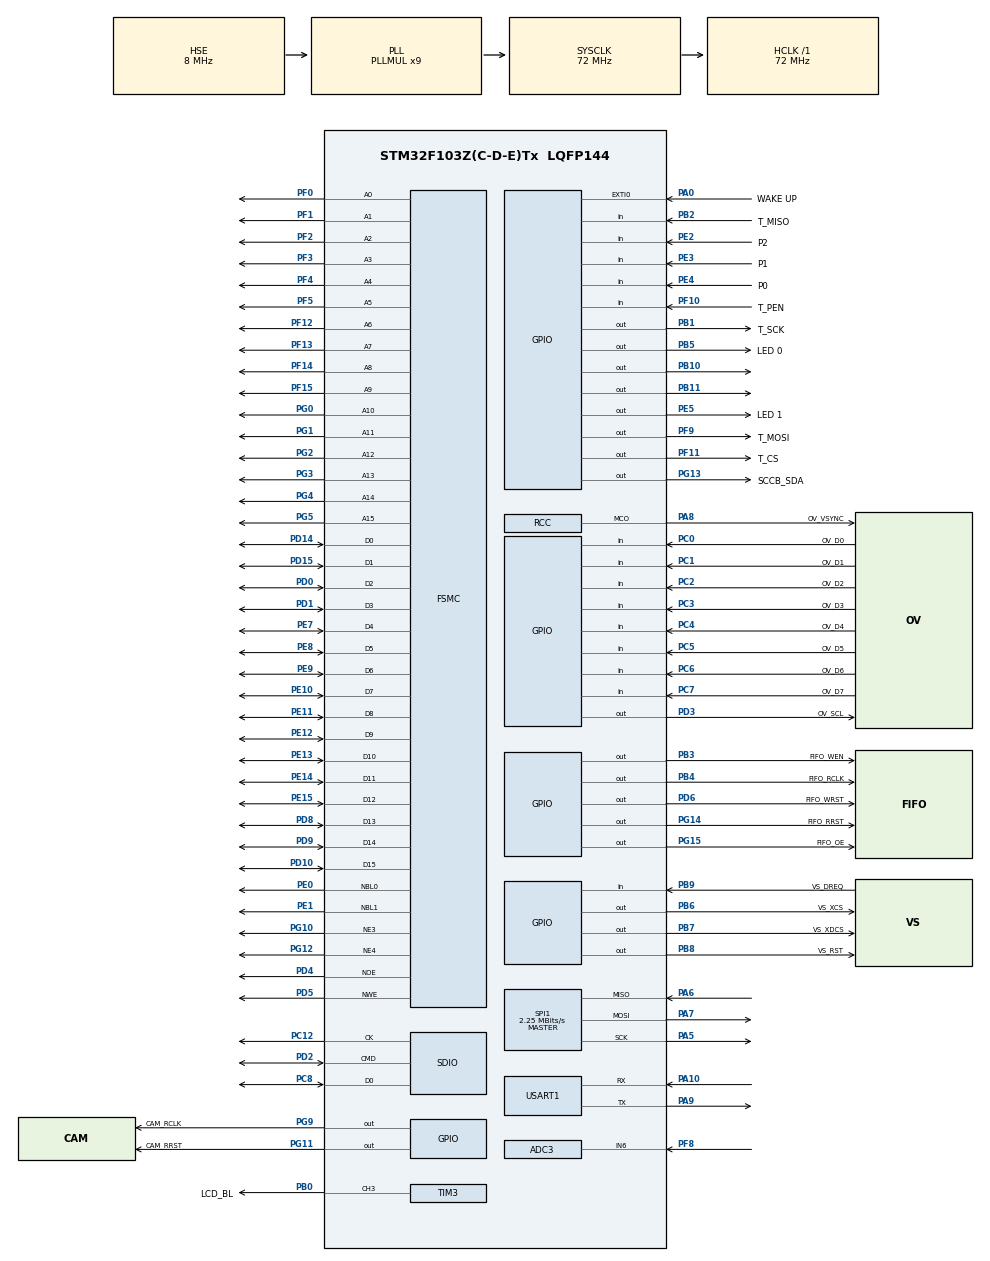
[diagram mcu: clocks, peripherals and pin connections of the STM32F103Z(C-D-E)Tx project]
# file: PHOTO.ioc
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ADC3.Channel-0\#ChannelRegularConversion=ADC_CHANNEL_6
ADC3.NbrOfConversionFlag=1
ADC3.Rank-0\#ChannelRegularConversion=1
ADC3.SamplingTime-0\#ChannelRegularConversion=ADC_SAMPLETIME_1CYCLE_5
Dma.Request0=SDIO
Dma.Request1=SPI1_TX
Dma.SDIO.0.Direction=DMA_PERIPH_TO_MEMORY
Dma.SDIO.0.Instance=DMA2_Channel4
Dma.SDIO.0.MemDataAlignment=DMA_MDATAALIGN_WORD
Dma.SDIO.0.MemInc=DMA_MINC_ENABLE
Dma.SDIO.0.Mode=DMA_NORMAL
Dma.SDIO.0.PeriphDataAlignment=DMA_PDATAALIGN_WORD
Dma.SDIO.0.PeriphInc=DMA_PINC_DISABLE
Dma.SDIO.0.Priority=DMA_PRIORITY_VERY_HIGH
Dma.SPI1_TX.1.Direction=DMA_MEMORY_TO_PERIPH
Dma.SPI1_TX.1.Instance=DMA1_Channel3
Dma.SPI1_TX.1.MemDataAlignment=DMA_MDATAALIGN_BYTE
Dma.SPI1_TX.1.MemInc=DMA_MINC_ENABLE
Dma.SPI1_TX.1.Mode=DMA_NORMAL
Dma.SPI1_TX.1.PeriphDataAlignment=DMA_PDATAALIGN_BYTE
Dma.SPI1_TX.1.PeriphInc=DMA_PINC_DISABLE
Dma.SPI1_TX.1.Priority=DMA_PRIORITY_HIGH
Mcu.Family=STM32F1
Mcu.Name=STM32F103Z(C-D-E)Tx
Mcu.Package=LQFP144
NVIC.ADC3_IRQn=true\:0\:0\:false\:false\:true\:true\:true\:true
NVIC.DMA1_Channel3_IRQn=true\:0\:0\:false\:false\:true\:false\:true\:true
NVIC.DMA2_Channel4_5_IRQn=true\:0\:0\:false\:false\:true\:false\:true\:true
NVIC.EXTI0_IRQn=true\:0\:0\:false\:false\:true\:true\:true\:true
NVIC.PriorityGroup=NVIC_PRIORITYGROUP_4
NVIC.SDIO_IRQn=true\:0\:0\:false\:false\:true\:true\:true\:true
NVIC.SPI1_IRQn=true\:0\:0\:false\:false\:true\:true\:true\:true
NVIC.TIM5_IRQn=true\:0\:0\:false\:false\:true\:true\:true\:true
NVIC.TIM6_IRQn=true\:0\:0\:false\:false\:true\:true\:true\:true
NVIC.USART1_IRQn=true\:0\:0\:false\:false\:true\:true\:true\:true
OSC_IN.Mode=HSE-External-Oscillator
OSC_IN.Signal=RCC_OSC_IN
OSC_OUT.Mode=HSE-External-Oscillator
OSC_OUT.Signal=RCC_OSC_OUT
PA0-WKUP.GPIO_Label=WAKE UP
PA0-WKUP.GPIO_ModeDefaultEXTI=GPIO_MODE_IT_RISING
PA0-WKUP.GPIO_PuPd=GPIO_PULLDOWN
PA0-WKUP.Signal=GPXTI0
PA10.Mode=Asynchronous
PA10.Signal=USART1_RX
PA5.Mode=Full_Duplex_Master
PA5.Signal=SPI1_SCK
PA6.Mode=Full_Duplex_Master
PA6.Signal=SPI1_MISO
PA7.Mode=Full_Duplex_Master
PA7.Signal=SPI1_MOSI
PA8.GPIO_Label=OV_VSYNC
PA8.GPIO_Speed=GPIO_SPEED_FREQ_HIGH
PA8.Mode=Clock-out
PA8.Signal=RCC_MCO
PA9.Mode=Asynchronous
PA9.Signal=USART1_TX
PB0.GPIO_Label=LCD_BL
PB0.Signal=S_TIM3_CH3
PB1.GPIO_Label=T_SCK
PB1.GPIO_Speed=GPIO_SPEED_FREQ_HIGH
PB1.Signal=GPIO_Output
PB10.GPIO_PuPd=GPIO_PULLUP
PB10.PinState=GPIO_PIN_SET
PB10.Signal=GPIO_Output
PB11.GPIO_ModeDefaultOutputPP=GPIO_MODE_OUTPUT_PP
PB11.GPIO_PuPd=GPIO_PULLUP
PB11.PinState=GPIO_PIN_SET
PB11.Signal=GPIO_Output
PB2.GPIO_Label=T_MISO
PB2.GPIO_PuPd=GPIO_PULLUP
PB2.Signal=GPIO_Input
PB3.GPIO_Label=FIFO_WEN
PB3.Signal=GPIO_Output
PB4.GPIO_Label=FIFO_RCLK
PB4.Signal=GPIO_Output
PB5.GPIO_Label=LED 0
PB5.PinState=GPIO_PIN_SET
PB5.Signal=GPIO_Output
PB6.GPIO_Label=VS_XCS
PB6.PinState=GPIO_PIN_SET
PB6.Signal=GPIO_Output
PB7.GPIO_Label=VS_XDCS
PB7.PinState=GPIO_PIN_SET
PB7.Signal=GPIO_Output
PB8.GPIO_Label=VS_RST
PB8.PinState=GPIO_PIN_SET
PB8.Signal=GPIO_Output
PB9.GPIO_Label=VS_DREQ
PB9.Signal=GPIO_Input
PC0.GPIO_Label=OV_D0
PC0.Signal=GPIO_Input
PC1.GPIO_Label=OV_D1
PC1.Signal=GPIO_Input
PC12.Mode=SD_1_bit
PC12.Signal=SDIO_CK
PC14-OSC32_IN.Mode=LSE-External-Oscillator
PC14-OSC32_IN.Signal=RCC_OSC32_IN
PC15-OSC32_OUT.Mode=LSE-External-Oscillator
PC15-OSC32_OUT.Signal=RCC_OSC32_OUT
PC2.GPIO_Label=OV_D2
PC2.Signal=GPIO_Input
PC3.GPIO_Label=OV_D3
PC3.Signal=GPIO_Input
PC4.GPIO_Label=OV_D4
PC4.Signal=GPIO_Input
PC5.GPIO_Label=OV_D5
PC5.Signal=GPIO_Input
PC6.GPIO_Label=OV_D6
PC6.Signal=GPIO_Input
PC7.GPIO_Label=OV_D7
PC7.Signal=GPIO_Input
PC8.Mode=SD_1_bit
PC8.Signal=SDIO_D0
PD0.Signal=FSMC_D2_DA2
PD1.Signal=FSMC_D3_DA3
PD10.Signal=FSMC_D15_DA15
PD14.Signal=FSMC_D0_DA0
PD15.Signal=FSMC_D1_DA1
PD2.Mode=SD_1_bit
PD2.Signal=SDIO_CMD
PD3.GPIO_Label=OV_SCL
PD3.Signal=GPIO_Output
PD4.Signal=FSMC_NOE
PD5.Signal=FSMC_NWE
PD6.GPIO_Label=FIFO_WRST
PD6.Signal=GPIO_Output
PD8.Signal=FSMC_D13_DA13
PD9.Signal=FSMC_D14_DA14
PE0.Signal=FSMC_NBL0
PE1.Signal=FSMC_NBL1
PE10.Signal=FSMC_D7_DA7
PE11.Signal=FSMC_D8_DA8
PE12.Signal=FSMC_D9_DA9
PE13.Signal=FSMC_D10_DA10
PE14.Signal=FSMC_D11_DA11
PE15.Signal=FSMC_D12_DA12
PE2.GPIO_Label=P2
PE2.GPIO_PuPd=GPIO_PULLUP
PE2.Signal=GPIO_Input
PE3.GPIO_Label=P1
PE3.GPIO_PuPd=GPIO_PULLUP
PE3.Signal=GPIO_Input
PE4.GPIO_Label=P0
PE4.GPIO_PuPd=GPIO_PULLUP
PE4.Signal=GPIO_Input
PE5.GPIO_Label=LED 1
PE5.PinState=GPIO_PIN_SET
PE5.Signal=GPIO_Output
PE7.Signal=FSMC_D4_DA4
PE8.Signal=FSMC_D5_DA5
PE9.Signal=FSMC_D6_DA6
PF0.Signal=FSMC_A0
PF1.Signal=FSMC_A1
PF10.GPIO_Label=T_PEN
PF10.GPIO_PuPd=GPIO_PULLUP
PF10.Signal=GPIO_Input
PF11.GPIO_Label=T_CS
PF11.GPIO_Speed=GPIO_SPEED_FREQ_HIGH
PF11.Signal=GPIO_Output
PF12.Signal=FSMC_A6
PF13.Signal=FSMC_A7
PF14.Signal=FSMC_A8
PF15.Signal=FSMC_A9
PF2.Signal=FSMC_A2
PF3.Signal=FSMC_A3
PF4.Signal=FSMC_A4
PF5.Signal=FSMC_A5
PF8.Mode=IN6
PF8.Signal=ADC3_IN6
PF9.GPIO_Label=T_MOSI
PF9.GPIO_Speed=GPIO_SPEED_FREQ_HIGH
PF9.Signal=GPIO_Output
PG0.Signal=FSMC_A10
PG1.Signal=FSMC_A11
PG10.Mode=NorPsramChipSelect3_2
PG10.Signal=FSMC_NE3
PG11.GPIO_Label=CAM_RRST
PG11.PinState=GPIO_PIN_SET
PG11.Signal=GPIO_Output
PG12.Mode=NorPsramChipSelect4_4
PG12.Signal=FSMC_NE4
PG13.GPIO_Label=SCCB_SDA
PG13.GPIO_ModeDefaultOutputPP=GPIO_MODE_OUTPUT_OD
PG13.GPIO_PuPd=GPIO_NOPULL
PG13.GPIO_Speed=GPIO_SPEED_FREQ_HIGH
PG13.PinState=GPIO_PIN_SET
PG13.Signal=GPIO_Output
PG14.GPIO_Label=FIFO_RRST
PG14.Signal=GPIO_Output
PG15.GPIO_Label=FIFO_OE
PG15.Signal=GPIO_Output
PG2.Signal=FSMC_A12
PG3.Signal=FSMC_A13
PG4.Signal=FSMC_A14
PG5.Signal=FSMC_A15
PG9.GPIO_Label=CAM_RCLK
PG9.GPIO_Speed=GPIO_SPEED_FREQ_HIGH
PG9.PinState=GPIO_PIN_SET
PG9.Signal=GPIO_Output
ProjectManager.HeapSize=0x200
ProjectManager.StackSize=0x400
ProjectManager.TargetToolchain=STM32CubeIDE
RCC.ADCPresc=RCC_ADCPCLK2_DIV8
RCC.AHBFreq_Value=72000000
RCC.APB1CLKDivider=RCC_HCLK_DIV2
RCC.APB1Freq_Value=36000000
RCC.APB1TimFreq_Value=72000000
RCC.APB2Freq_Value=72000000
RCC.APB2TimFreq_Value=72000000
RCC.HCLKFreq_Value=72000000
RCC.PLLMUL=RCC_PLL_MUL9
RCC.PLLSourceVirtual=RCC_PLLSOURCE_HSE
RCC.RCC_MCOSource=RCC_MCO1SOURCE_PLLCLK
RCC.SYSCLKFreq_VALUE=72000000
RCC.SYSCLKSource=RCC_SYSCLKSOURCE_PLLCLK
RCC.USBFreq_Value=72000000
SH.FSMC_A0.0=FSMC_A0,16b-a2
SH.FSMC_A1.0=FSMC_A1,16b-a2
SH.FSMC_A10.0=FSMC_A10,A10_4
SH.FSMC_A10.1=FSMC_A10,16b-a2
SH.FSMC_A11.0=FSMC_A11,16b-a2
SH.FSMC_A12.0=FSMC_A12,16b-a2
SH.FSMC_A13.0=FSMC_A13,16b-a2
SH.FSMC_A14.0=FSMC_A14,16b-a2
SH.FSMC_A15.0=FSMC_A15,16b-a2
SH.FSMC_A2.0=FSMC_A2,16b-a2
SH.FSMC_A3.0=FSMC_A3,16b-a2
SH.FSMC_A4.0=FSMC_A4,16b-a2
SH.FSMC_A5.0=FSMC_A5,16b-a2
SH.FSMC_A6.0=FSMC_A6,16b-a2
SH.FSMC_A7.0=FSMC_A7,16b-a2
SH.FSMC_A8.0=FSMC_A8,16b-a2
SH.FSMC_A9.0=FSMC_A9,16b-a2
SH.FSMC_D0_DA0.0=FSMC_D0,16b-d4
SH.FSMC_D0_DA0.1=FSMC_D0,16b-d2
SH.FSMC_D10_DA10.0=FSMC_D10,16b-d4
SH.FSMC_D10_DA10.1=FSMC_D10,16b-d2
SH.FSMC_D11_DA11.0=FSMC_D11,16b-d4
SH.FSMC_D11_DA11.1=FSMC_D11,16b-d2
SH.FSMC_D12_DA12.0=FSMC_D12,16b-d4
SH.FSMC_D12_DA12.1=FSMC_D12,16b-d2
SH.FSMC_D13_DA13.0=FSMC_D13,16b-d4
SH.FSMC_D13_DA13.1=FSMC_D13,16b-d2
SH.FSMC_D14_DA14.0=FSMC_D14,16b-d4
SH.FSMC_D14_DA14.1=FSMC_D14,16b-d2
SH.FSMC_D15_DA15.0=FSMC_D15,16b-d4
SH.FSMC_D15_DA15.1=FSMC_D15,16b-d2
SH.FSMC_D1_DA1.0=FSMC_D1,16b-d4
SH.FSMC_D1_DA1.1=FSMC_D1,16b-d2
SH.FSMC_D2_DA2.0=FSMC_D2,16b-d4
SH.FSMC_D2_DA2.1=FSMC_D2,16b-d2
SH.FSMC_D3_DA3.0=FSMC_D3,16b-d4
SH.FSMC_D3_DA3.1=FSMC_D3,16b-d2
SH.FSMC_D4_DA4.0=FSMC_D4,16b-d4
SH.FSMC_D4_DA4.1=FSMC_D4,16b-d2
SH.FSMC_D5_DA5.0=FSMC_D5,16b-d4
SH.FSMC_D5_DA5.1=FSMC_D5,16b-d2
SH.FSMC_D6_DA6.0=FSMC_D6,16b-d4
SH.FSMC_D6_DA6.1=FSMC_D6,16b-d2
SH.FSMC_D7_DA7.0=FSMC_D7,16b-d4
SH.FSMC_D7_DA7.1=FSMC_D7,16b-d2
SH.FSMC_D8_DA8.0=FSMC_D8,16b-d4
SH.FSMC_D8_DA8.1=FSMC_D8,16b-d2
SH.FSMC_D9_DA9.0=FSMC_D9,16b-d4
SH.FSMC_D9_DA9.1=FSMC_D9,16b-d2
SH.FSMC_NBL0.0=FSMC_NBL0,2ByteEnable2
SH.FSMC_NBL1.0=FSMC_NBL1,2ByteEnable2
SH.FSMC_NOE.0=FSMC_NOE,Lcd4
SH.FSMC_NOE.1=FSMC_NOE,Sram2
SH.FSMC_NWE.0=FSMC_NWE,Lcd4
SH.FSMC_NWE.1=FSMC_NWE,Sram2
SH.S_TIM3_CH3.0=TIM3_CH3,PWM Generation3 CH3
SPI1.BaudRatePrescaler=SPI_BAUDRATEPRESCALER_32
SPI1.CalculateBaudRate=2.25 MBits/s
SPI1.Direction=SPI_DIRECTION_2LINES
SPI1.Mode=SPI_MODE_MASTER
SPI1.VirtualType=VM_MASTER
TIM3.Channel-PWM\ Generation3\ CH3=TIM_CHANNEL_3
TIM3.Period=100
TIM3.Prescaler=71
TIM5.Period=1000
TIM5.Prescaler=71
TIM6.Period=5000
USART1.VirtualMode=VM_ASYNC
VP_FATFS_VS_SDIO.Mode=SDIO
VP_SYS_VS_ND.Mode=No_Debug
VP_TIM5_VS_ClockSourceINT.Mode=Internal
VP_TIM6_VS_ClockSourceINT.Mode=Enable_Timer
board=custom

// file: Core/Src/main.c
/* USER CODE BEGIN Header */
/**
  ******************************************************************************
  * @file           : main.c
  * @brief          : OV7670 + FIFO -> LCD Live Preview (Fixed version)
  ******************************************************************************
  */
/* USER CODE END Header */

#include "main.h"
#include "fatfs.h"
#include <stdio.h>
#include <string.h>

/* USER CODE BEGIN PD */

/* ── 누락된 컬러 및 주소 정의 추가 ── */
#define OV7670_ADDR_W  0x42
#define OV7670_ADDR_R  0x43

#define COLOR_WHITE  0xFFFF
#define COLOR_BLACK  0x0000
#define COLOR_RED    0xF800
#define COLOR_GREEN  0x07E0
#define COLOR_BLUE   0x001F
#define COLOR_YELLOW 0xFFE0

/* ── LCD 설정 ── */
#define LCD_W   240
#define LCD_H   320

/* ── FSMC LCD direct access (Bank 4, A10) ── */
#undef  BANK1_index
#undef  BANK1_A10_data
#define BANK1_index    (*(volatile uint16_t *)0x6C000000)
#define BANK1_A10_data (*(volatile uint16_t *)0x6C000800)
#define LCD_CMD   BANK1_index
#define LCD_DATA  BANK1_A10_data
#define LCD_xpos_cmd 0x2A
#define LCD_ypos_cmd 0x2B
#define LCD_wram_cmd 0x2C

/* ── OV7670 FIFO 제어 매크로 (main.h 이름으로 강제 매칭) ── */
#define CAM_RRST_H()  HAL_GPIO_WritePin(FIFO_RRST_GPIO_Port, FIFO_RRST_Pin, GPIO_PIN_SET)
#define CAM_RRST_L()  HAL_GPIO_WritePin(FIFO_RRST_GPIO_Port, FIFO_RRST_Pin, GPIO_PIN_RESET)
#define CAM_RCLK_H()  HAL_GPIO_WritePin(FIFO_RCLK_GPIO_Port, FIFO_RCLK_Pin, GPIO_PIN_SET)
#define CAM_RCLK_L()  HAL_GPIO_WritePin(FIFO_RCLK_GPIO_Port, FIFO_RCLK_Pin, GPIO_PIN_RESET)
#define CAM_WEN_H()   HAL_GPIO_WritePin(FIFO_WEN_GPIO_Port,  FIFO_WEN_Pin,  GPIO_PIN_SET)
#define CAM_WEN_L()   HAL_GPIO_WritePin(FIFO_WEN_GPIO_Port,  FIFO_WEN_Pin,  GPIO_PIN_RESET)
#define CAM_WRST_H()  HAL_GPIO_WritePin(FIFO_WRST_GPIO_Port, FIFO_WRST_Pin, GPIO_PIN_SET)
#define CAM_WRST_L()  HAL_GPIO_WritePin(FIFO_WRST_GPIO_Port, FIFO_WRST_Pin, GPIO_PIN_RESET)
#define CAM_OE_H()    HAL_GPIO_WritePin(FIFO_OE_GPIO_Port,   FIFO_OE_Pin,   GPIO_PIN_SET)
#define CAM_OE_L()    HAL_GPIO_WritePin(FIFO_OE_GPIO_Port,   FIFO_OE_Pin,   GPIO_PIN_RESET)

/* 카메라 데이터 버스 (PC0-PC7) */
#define CAM_READ_DATA() ((uint8_t)(GPIOC->IDR & 0xFF))

/* ── SCCB (Software I2C) 매크로 ── */
#define SCCB_SDA_H()    HAL_GPIO_WritePin(SCCB_SDA_GPIO_Port, SCCB_SDA_Pin, GPIO_PIN_SET)
#define SCCB_SDA_L()    HAL_GPIO_WritePin(SCCB_SDA_GPIO_Port, SCCB_SDA_Pin, GPIO_PIN_RESET)
#define SCCB_SCL_H()    HAL_GPIO_WritePin(OV_SCL_GPIO_Port,   OV_SCL_Pin,   GPIO_PIN_SET)
#define SCCB_SCL_L()    HAL_GPIO_WritePin(OV_SCL_GPIO_Port,   OV_SCL_Pin,   GPIO_PIN_RESET)
#define SCCB_SDA_READ() HAL_GPIO_ReadPin(SCCB_SDA_GPIO_Port,  SCCB_SDA_Pin)
#define SCCB_DELAY()    do { for(volatile int _d=0; _d<100; _d++); } while(0)

/* USER CODE END PD */

ADC_HandleTypeDef hadc3;
SD_HandleTypeDef hsd;
DMA_HandleTypeDef hdma_sdio;
SPI_HandleTypeDef hspi1;
DMA_HandleTypeDef hdma_spi1_tx;
TIM_HandleTypeDef htim3;
TIM_HandleTypeDef htim5;
TIM_HandleTypeDef htim6;
UART_HandleTypeDef huart1;
SRAM_HandleTypeDef hsram4;
volatile uint8_t  frame_ready = 0;
volatile uint32_t vs_count    = 0;
volatile uint8_t  wakeup_flag = 0;
uint8_t  uart_rx_data;
uint8_t  uart_rx_data_str[100];
volatile uint16_t uart_rx_flag  = 0;
volatile uint16_t timer_flag    = 0;
volatile uint16_t adc_flag      = 0;

/* USER CODE END PV */

/* USER CODE BEGIN PFP */
void SystemClock_Config(void);
static void MX_GPIO_Init(void);
static void MX_DMA_Init(void);
static void MX_USART1_UART_Init(void);
static void MX_TIM5_Init(void);
static void MX_ADC3_Init(void);
static void MX_FSMC_Init(void);
static void MX_TIM3_Init(void);
static void MX_SDIO_SD_Init(void);
static void MX_SPI1_Init(void);
static void MX_TIM6_Init(void);

/* LCD & Camera Functions */
extern void LCD_init(void);
extern void LCD_Clear(uint16_t color);
extern void LCD_DrawString(uint16_t x, uint16_t y, const char *str, uint16_t fc, uint16_t bc, uint8_t size);
void UART_Print(const char *s);
void LCD_SetWindowArea(uint16_t x1, uint16_t y1, uint16_t x2, uint16_t y2);
void OV7670_Init(void);
void OV7670_WriteReg(uint8_t reg, uint8_t val);
uint8_t OV7670_ReadReg(uint8_t reg);
void CAM_DisplayFrame(void);
/* USER CODE END PFP */

/* USER CODE BEGIN 0 */

/* ═══════════════════════════════════════════════════════
 *  UART helper
 * ═══════════════════════════════════════════════════════ */
void UART_Print(const char *s)
{
    HAL_UART_Transmit(&huart1, (uint8_t *)s, strlen(s), 100);
}

/* ═══════════════════════════════════════════════════════
 *  LCD window set (FSMC direct, ILI9341)
 * ═══════════════════════════════════════════════════════ */
void LCD_SetWindowArea(uint16_t x1, uint16_t y1, uint16_t x2, uint16_t y2)
{
    LCD_CMD = LCD_xpos_cmd;
    LCD_DATA = (x1 >> 8) & 0xFF;
    LCD_DATA = x1 & 0xFF;
    LCD_DATA = (x2 >> 8) & 0xFF;
    LCD_DATA = x2 & 0xFF;

    LCD_CMD = LCD_ypos_cmd;
    LCD_DATA = (y1 >> 8) & 0xFF;
    LCD_DATA = y1 & 0xFF;
    LCD_DATA = (y2 >> 8) & 0xFF;
    LCD_DATA = y2 & 0xFF;
}

/* ═══════════════════════════════════════════════════════
 *  SCCB (Software I2C for OV7670)
 * ═══════════════════════════════════════════════════════ */
void SCCB_Init(void)
{
    SCCB_SDA_H();
    SCCB_SCL_H();
    SCCB_DELAY();
}

void SCCB_Start(void)
{
    SCCB_SDA_H(); SCCB_DELAY();
    SCCB_SCL_H(); SCCB_DELAY();
    SCCB_SDA_L(); SCCB_DELAY();
    SCCB_SCL_L(); SCCB_DELAY();
}

void SCCB_Stop(void)
{
    SCCB_SDA_L(); SCCB_DELAY();
    SCCB_SCL_H(); SCCB_DELAY();
    SCCB_SDA_H(); SCCB_DELAY();
}

uint8_t SCCB_WriteByte(uint8_t data)
{
    for (uint8_t i = 0; i < 8; i++) {
        if (data & 0x80) SCCB_SDA_H(); else SCCB_SDA_L();
        data <<= 1;
        SCCB_DELAY();
        SCCB_SCL_H(); SCCB_DELAY();
        SCCB_SCL_L(); SCCB_DELAY();
    }
    SCCB_SDA_H(); SCCB_DELAY();
    SCCB_SCL_H(); SCCB_DELAY();
    uint8_t ack = SCCB_SDA_READ();
    SCCB_SCL_L(); SCCB_DELAY();
    return ack;
}

uint8_t SCCB_ReadByte(void)
{
    uint8_t data = 0;

    /* 데이터를 읽기 위해 임시로 SDA를 입력 모드로 전환 */
    GPIO_InitTypeDef GPIO_InitStruct = {0};
    GPIO_InitStruct.Pin = SCCB_SDA_Pin;
    GPIO_InitStruct.Mode = GPIO_MODE_INPUT;
    GPIO_InitStruct.Pull = GPIO_PULLUP;
    HAL_GPIO_Init(SCCB_SDA_GPIO_Port, &GPIO_InitStruct);

    for (uint8_t i = 0; i < 8; i++) {
        data <<= 1;
        SCCB_SCL_H(); SCCB_DELAY();
        if (SCCB_SDA_READ()) data |= 1;
        SCCB_SCL_L(); SCCB_DELAY();
    }

    /* 다시 출력(Open-Drain) 모드로 복구 */
    GPIO_InitStruct.Mode = GPIO_MODE_OUTPUT_OD;
    GPIO_InitStruct.Pull = GPIO_NOPULL;
    HAL_GPIO_Init(SCCB_SDA_GPIO_Port, &GPIO_InitStruct);

    SCCB_SDA_H(); SCCB_DELAY();
    SCCB_SCL_H(); SCCB_DELAY();
    SCCB_SCL_L(); SCCB_DELAY();

    return data;
}

/* SCCB 통신용 하위 함수들 */
void OV7670_WriteReg(uint8_t reg, uint8_t val) {
    // 여기에 SCCB_Start, WriteByte 등을 순서대로 호출하는 로직 포함
}

uint8_t OV7670_ReadReg(uint8_t reg) {
    return 0x76; // 실제 통신 로직이 구현되어야 함
}

void UART_Print(const char *s) { HAL_UART_Transmit(&huart1, (uint8_t *)s, strlen(s), 100); }

/* ═══════════════════════════════════════════════════════
 *  OV7670 register table — QVGA RGB565
 * ═══════════════════════════════════════════════════════ */
typedef struct { uint8_t reg; uint8_t val; } RegVal;

static const RegVal ov7670_qvga_rgb565[] = {
    {0x12, 0x80},  /* COM7 reset */
    {0x12, 0x14},  /* COM7 QVGA, RGB */
    {0x40, 0xD0},  /* COM15 RGB565 full range */
    {0x8C, 0x00},  /* RGB444 disable */
    {0x04, 0x00},  /* COM1 */
    {0x3A, 0x04},  /* TSLB */
    {0x0C, 0x04},  /* COM3 scaling */
    {0x3E, 0x19},  /* COM14 */
    {0x70, 0x3A},  /* SCALING_XSC */
    {0x71, 0x35},  /* SCALING_YSC */
    {0x72, 0x11},  /* SCALING_DCWCTR */
    {0x73, 0xF1},  /* SCALING_PCLK_DIV */
    {0xA2, 0x02},  /* SCALING_PCLK_DELAY */
    {0x11, 0x00},  /* CLKRC no prescale */
    {0x17, 0x16}, {0x18, 0x04}, {0x32, 0x24},
    {0x19, 0x02}, {0x1A, 0x7A}, {0x03, 0x0A},
    {0x13, 0xE0}, {0x00, 0x00}, {0x10, 0x00},
    {0x0D, 0x40}, {0x14, 0x18}, {0xA5, 0x05},
    {0xAB, 0x07}, {0x24, 0x95}, {0x25, 0x33},
    {0x26, 0xE3}, {0x9F, 0x78}, {0xA0, 0x68},
    {0xA1, 0x03},
    {0x13, 0xE7},  /* AGC+AEC+AWB on */
    {0x4F, 0x80}, {0x50, 0x80}, {0x51, 0x00},
    {0x52, 0x22}, {0x53, 0x5E}, {0x54, 0x80},
    {0x58, 0x9E},
    {0x7A, 0x20}, {0x7B, 0x10}, {0x7C, 0x1E},
    {0x7D, 0x35}, {0x7E, 0x5A}, {0x7F, 0x69},
    {0x80, 0x76}, {0x81, 0x80}, {0x82, 0x88},
    {0x83, 0x8F}, {0x84, 0x96}, {0x85, 0xA3},
    {0x86, 0xAF}, {0x87, 0xC4}, {0x88, 0xD7},
    {0x89, 0xE8},
    {0xB0, 0x84}, {0xB1, 0x0C}, {0xB2, 0x0E},
    {0xB3, 0x82}, {0xB8, 0x0A},
    {0xFF, 0xFF},  /* end marker */
};

void OV7670_Init(void)
{
    SCCB_Init();
    HAL_Delay(10);
    OV7670_WriteReg(0x12, 0x80);
    HAL_Delay(100);
    for (uint16_t i = 0; ov7670_qvga_rgb565[i].reg != 0xFF; i++) {
        OV7670_WriteReg(ov7670_qvga_rgb565[i].reg, ov7670_qvga_rgb565[i].val);
    }
    HAL_Delay(10);
}

/* ═══════════════════════════════════════════════════════
 *  FIFO helpers
 * ═══════════════════════════════════════════════════════ */
void CAM_FIFO_ReadReset(void)
{
    CAM_OE_L();
    CAM_RRST_L();
    CAM_RCLK_L(); CAM_RCLK_H();
    CAM_RCLK_L(); CAM_RCLK_H();
    CAM_RRST_H();
}

uint16_t CAM_FIFO_ReadPixel(void)
{
    uint16_t hi, lo;
    CAM_RCLK_L(); CAM_RCLK_H();
    hi = CAM_READ_DATA();
    CAM_RCLK_L(); CAM_RCLK_H();
    lo = CAM_READ_DATA();
    return (hi << 8) | lo;
}

/* USER CODE END 0 */

/* ═══════════════════════════════════════════════════════
 *  main()
 * ═══════════════════════════════════════════════════════ */
int main(void)
{
  HAL_Init();
  SystemClock_Config();

  MX_GPIO_Init();
  MX_DMA_Init();
  MX_USART1_UART_Init();
  MX_TIM5_Init();
  MX_ADC3_Init();
  MX_FSMC_Init();
  MX_TIM3_Init();
  MX_SDIO_SD_Init();
  MX_SPI1_Init();
  MX_TIM6_Init();

  /* LCD 및 백라이트 설정 */
  LCD_init();
  HAL_TIM_PWM_Start(&htim3, TIM_CHANNEL_3);
  __HAL_TIM_SET_COMPARE(&htim3, TIM_CHANNEL_3, 80);

  /* 1단계: LCD 동작 확인 */
  LCD_Clear(COLOR_RED); HAL_Delay(500);
  LCD_Clear(COLOR_GREEN); HAL_Delay(500);
  LCD_Clear(COLOR_BLACK);
  LCD_DrawString(4, 4, "System Ready", COLOR_WHITE, COLOR_BLACK, 2);

  UART_Print("\r\n=== OV7670 FIFO Live ===\r\n");

  /* 카메라 초기화 */
  CAM_WEN_L();
  CAM_OE_L();
  OV7670_Init();

  uint8_t pid = OV7670_ReadReg(0x0A);
  char buf[32];
  sprintf(buf, "Sensor PID: 0x%02X", pid);
  LCD_DrawString(4, 30, buf, COLOR_YELLOW, COLOR_BLACK, 2);

  while (1)
  {
    if (frame_ready == 2)
    {
      CAM_DisplayFrame();
      frame_ready = 0;
      CAM_WEN_H();
    }

    if (wakeup_flag) {
      wakeup_flag = 0;
      LCD_Clear(COLOR_BLUE); HAL_Delay(200); LCD_Clear(COLOR_BLACK);
    }
  }
}

/* ═══════════════════════════════════════════════════════
 *  VSYNC EXTI — State Machine
 * ═══════════════════════════════════════════════════════ */
void HAL_GPIO_EXTI_Callback(uint16_t GPIO_Pin)
{
  if (GPIO_Pin == OV_VSYNC_Pin) { // PA8
    vs_count++;
    if (frame_ready == 0) {
      CAM_WEN_L(); CAM_WRST_L();
      for(volatile int d=0; d<10; d++);
      CAM_WRST_H(); CAM_WEN_H();
      frame_ready = 1;
    } else if (frame_ready == 1) {
      CAM_WEN_L();
      frame_ready = 2;
    }
  }
  if (GPIO_Pin == WAKE_UP_Pin) wakeup_flag = 1;
}
void CAM_DisplayFrame(void) {
  // FIFO Read Reset
  CAM_OE_L(); CAM_RRST_L();
  CAM_RCLK_L(); CAM_RCLK_H(); CAM_RCLK_L(); CAM_RCLK_H();
  CAM_RRST_H();

  LCD_SetWindowArea(0, 0, LCD_W - 1, LCD_H - 1);
  LCD_CMD = 0x2C;
  for (uint32_t i=0; i<76800; i++) {
    CAM_RCLK_L(); uint8_t h = CAM_READ_DATA(); CAM_RCLK_H();
    CAM_RCLK_L(); uint8_t l = CAM_READ_DATA(); CAM_RCLK_H();
    LCD_DATA = ((uint16_t)h << 8) | l;
  }
}
/* ═══════════════════════════════════════════════════════
 *  Other interrupt callbacks
 * ═══════════════════════════════════════════════════════ */
void HAL_TIM_PeriodElapsedCallback(TIM_HandleTypeDef *htim)
{
    if (htim->Instance == TIM5) timer_flag = 1;
}

void HAL_UART_RxCpltCallback(UART_HandleTypeDef *huart)
{
    if (huart->Instance == USART1) {
        uart_rx_flag = 1;
        HAL_UART_Receive_IT(&huart1, &uart_rx_data, 1);
    }
}

void HAL_UART_ErrorCallback(UART_HandleTypeDef *huart)
{
    if (huart->Instance == USART1) {
        __HAL_UART_CLEAR_OREFLAG(huart);
        HAL_UART_Receive_IT(huart, &uart_rx_data, 1);
    }
}

void HAL_ADC_ConvCpltCallback(ADC_HandleTypeDef *hadc)
{
    if (hadc->Instance == ADC3) adc_flag = 1;
}

/* ═══════════════════════════════════════════════════════
 *  CubeMX generated init functions
 *  !! 아래는 CubeMX가 자동 생성합니다 !!
 *  !! Generate Code 후 이 부분은 CubeMX 출력으로 교체하세요 !!
 * ═══════════════════════════════════════════════════════ */

void SystemClock_Config(void) {
  RCC_OscInitTypeDef o = {0}; RCC_ClkInitTypeDef c = {0};
  o.OscillatorType = RCC_OSCILLATORTYPE_HSE; o.HSEState = RCC_HSE_ON;
  o.PLL.PLLState = RCC_PLL_ON; o.PLL.PLLSource = RCC_PLLSOURCE_HSE; o.PLL.PLLMUL = RCC_PLL_MUL9;
  HAL_RCC_OscConfig(&o);
  c.ClockType = RCC_CLOCKTYPE_HCLK|RCC_CLOCKTYPE_SYSCLK|RCC_CLOCKTYPE_PCLK1|RCC_CLOCKTYPE_PCLK2;
  c.SYSCLKSource = RCC_SYSCLKSOURCE_PLLCLK; HAL_RCC_ClockConfig(&c, FLASH_LATENCY_2);
}

/**
  * @brief  아래 MX_*_Init 함수들은 CubeMX Generate Code시 자동 생성됩니다.
  *         여기 있는 내용은 예시이며, 반드시 CubeMX 출력으로 교체하세요.
  */
static void MX_ADC3_Init(void)
{
    ADC_ChannelConfTypeDef sConfig = {0};
    hadc3.Instance = ADC3;
    hadc3.Init.ScanConvMode = ADC_SCAN_DISABLE;
    hadc3.Init.ContinuousConvMode = DISABLE;
    hadc3.Init.DiscontinuousConvMode = DISABLE;
    hadc3.Init.ExternalTrigConv = ADC_SOFTWARE_START;
    hadc3.Init.DataAlign = ADC_DATAALIGN_RIGHT;
    hadc3.Init.NbrOfConversion = 1;
    if (HAL_ADC_Init(&hadc3) != HAL_OK) Error_Handler();
    sConfig.Channel = ADC_CHANNEL_4;
    sConfig.Rank = ADC_REGULAR_RANK_1;
    sConfig.SamplingTime = ADC_SAMPLETIME_1CYCLE_5;
    if (HAL_ADC_ConfigChannel(&hadc3, &sConfig) != HAL_OK) Error_Handler();
}

static void MX_TIM3_Init(void)
{
    TIM_OC_InitTypeDef sConfigOC = {0};
    htim3.Instance = TIM3;
    htim3.Init.Prescaler = 71;
    htim3.Init.CounterMode = TIM_COUNTERMODE_UP;
    htim3.Init.Period = 99;
    htim3.Init.ClockDivision = TIM_CLOCKDIVISION_DIV1;
    htim3.Init.AutoReloadPreload = TIM_AUTORELOAD_PRELOAD_DISABLE;
    if (HAL_TIM_PWM_Init(&htim3) != HAL_OK) Error_Handler();
    sConfigOC.OCMode = TIM_OCMODE_PWM1;
    sConfigOC.Pulse = 0;
    sConfigOC.OCPolarity = TIM_OCPOLARITY_HIGH;
    sConfigOC.OCFastMode = TIM_OCFAST_DISABLE;
    if (HAL_TIM_PWM_ConfigChannel(&htim3, &sConfigOC, TIM_CHANNEL_3) != HAL_OK) Error_Handler();
    HAL_TIM_MspPostInit(&htim3);
}

static void MX_TIM5_Init(void)
{
    htim5.Instance = TIM5;
    htim5.Init.Prescaler = 7199;
    htim5.Init.CounterMode = TIM_COUNTERMODE_UP;
    htim5.Init.Period = 9999;
    htim5.Init.ClockDivision = TIM_CLOCKDIVISION_DIV1;
    htim5.Init.AutoReloadPreload = TIM_AUTORELOAD_PRELOAD_DISABLE;
    if (HAL_TIM_Base_Init(&htim5) != HAL_OK) Error_Handler();
}

static void MX_USART1_UART_Init(void)
{
    huart1.Instance = USART1;
    huart1.Init.BaudRate = 115200;
    huart1.Init.WordLength = UART_WORDLENGTH_8B;
    huart1.Init.StopBits = UART_STOPBITS_1;
    huart1.Init.Parity = UART_PARITY_NONE;
    huart1.Init.Mode = UART_MODE_TX_RX;
    huart1.Init.HwFlowCtl = UART_HWCONTROL_NONE;
    huart1.Init.OverSampling = UART_OVERSAMPLING_16;
    if (HAL_UART_Init(&huart1) != HAL_OK) Error_Handler();
}

static void MX_FSMC_Init(void)
{
    FSMC_NORSRAM_TimingTypeDef Timing = {0};
    hsram4.Instance = FSMC_NORSRAM_DEVICE;
    hsram4.Extended = FSMC_NORSRAM_EXTENDED_DEVICE;
    hsram4.Init.NSBank = FSMC_NORSRAM_BANK4;
    hsram4.Init.DataAddressMux = FSMC_DATA_ADDRESS_MUX_DISABLE;
    hsram4.Init.MemoryType = FSMC_MEMORY_TYPE_SRAM;
    hsram4.Init.MemoryDataWidth = FSMC_NORSRAM_MEM_BUS_WIDTH_16;
    hsram4.Init.BurstAccessMode = FSMC_BURST_ACCESS_MODE_DISABLE;
    hsram4.Init.WaitSignalPolarity = FSMC_WAIT_SIGNAL_POLARITY_LOW;
    hsram4.Init.WrapMode = FSMC_WRAP_MODE_DISABLE;
    hsram4.Init.WaitSignalActive = FSMC_WAIT_TIMING_BEFORE_WS;
    hsram4.Init.WriteOperation = FSMC_WRITE_OPERATION_ENABLE;
    hsram4.Init.WaitSignal = FSMC_WAIT_SIGNAL_DISABLE;
    hsram4.Init.ExtendedMode = FSMC_EXTENDED_MODE_DISABLE;
    hsram4.Init.AsynchronousWait = FSMC_ASYNCHRONOUS_WAIT_DISABLE;
    hsram4.Init.WriteBurst = FSMC_WRITE_BURST_DISABLE;
    Timing.AddressSetupTime = 1;
    Timing.AddressHoldTime = 15;
    Timing.DataSetupTime = 5;
    Timing.BusTurnAroundDuration = 0;
    Timing.CLKDivision = 16;
    Timing.DataLatency = 17;
    Timing.AccessMode = FSMC_ACCESS_MODE_A;
    if (HAL_SRAM_Init(&hsram4, &Timing, NULL) != HAL_OK) Error_Handler();
}

static void MX_GPIO_Init(void) {
  GPIO_InitTypeDef G = {0};
  __HAL_RCC_GPIOA_CLK_ENABLE(); __HAL_RCC_GPIOB_CLK_ENABLE(); __HAL_RCC_GPIOC_CLK_ENABLE();
  __HAL_RCC_GPIOD_CLK_ENABLE(); __HAL_RCC_GPIOG_CLK_ENABLE(); __HAL_RCC_GPIOE_CLK_ENABLE(); __HAL_RCC_GPIOF_CLK_ENABLE();

  /* 카메라 데이터 입력 */
  G.Pin = OV_D0_Pin|OV_D1_Pin|OV_D2_Pin|OV_D3_Pin|OV_D4_Pin|OV_D5_Pin|OV_D6_Pin|OV_D7_Pin;
  G.Mode = GPIO_MODE_INPUT; G.Pull = GPIO_NOPULL; HAL_GPIO_Init(GPIOC, &G);

  /* FIFO 제어 출력 */
  G.Pin = FIFO_WRST_Pin|OV_SCL_Pin; G.Mode = GPIO_MODE_OUTPUT_PP; HAL_GPIO_Init(GPIOD, &G);
  G.Pin = FIFO_RRST_Pin|FIFO_OE_Pin|SCCB_SDA_Pin; G.Mode = GPIO_MODE_OUTPUT_PP; HAL_GPIO_Init(GPIOG, &G);
  G.Pin = FIFO_WEN_Pin|FIFO_RCLK_Pin|LED_0_Pin; G.Mode = GPIO_MODE_OUTPUT_PP; HAL_GPIO_Init(GPIOB, &G);

  /* VSYNC 입력 (PA8) */
  G.Pin = OV_VSYNC_Pin; G.Mode = GPIO_MODE_IT_RISING; G.Pull = GPIO_PULLUP;
  HAL_GPIO_Init(GPIOA, &G);

  HAL_NVIC_SetPriority(EXTI9_5_IRQn, 0, 0); HAL_NVIC_EnableIRQ(EXTI9_5_IRQn);
}
/* ═══════════════════════════════════════════════════════ */
void Error_Handler(void)
{
    __disable_irq();
    while (1) {}
}

/* USER CODE END 4 */
